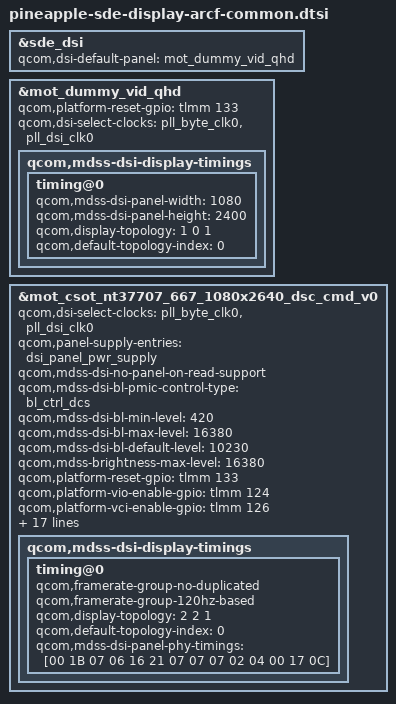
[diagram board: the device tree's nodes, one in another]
/* This is derivated from qcom pineapple-sde-display-mtp.dtsi */

#include "pineapple-sde-display.dtsi"
#include "dsi-panel-mot-dummy-qhd-video.dtsi"
#include "dsi-panel-mot-csot-nt37707-667-1080x2640-dsc-cmd-common_v0.dtsi"

&sde_dsi {
	qcom,dsi-default-panel = <&mot_dummy_vid_qhd>;
};

&mot_dummy_vid_qhd {
       qcom,mdss-dsi-display-timings {
                timing@0{
                       qcom,mdss-dsi-panel-width = <1080>;
                       qcom,mdss-dsi-panel-height = <2400>;
               };
       };
};

//&L11B {
//       regulator-min-microvolt = <1230000>;
//       regulator-max-microvolt = <1280000>;
//       qcom,init-voltage = <1250000>;
//};

//&sde_dsi1 {
//	vddio-supply = <&L10B>;
//	vdd-supply = <&L11B>;
//	vci-supply = <&L9B>;
//};

&mot_csot_nt37707_667_1080x2640_dsc_cmd_v0 {
	qcom,dsi-select-clocks = "pll_byte_clk0", "pll_dsi_clk0";
	qcom,panel-supply-entries = <&dsi_panel_pwr_supply>;
	qcom,mdss-dsi-no-panel-on-read-support;
	qcom,mdss-dsi-bl-pmic-control-type = "bl_ctrl_dcs";
	qcom,mdss-dsi-bl-min-level = <420>;
	qcom,mdss-dsi-bl-max-level = <16380>;
	qcom,mdss-dsi-bl-default-level = <10230>;
	qcom,mdss-brightness-max-level = <16380>;
	qcom,platform-reset-gpio = <&tlmm 133 0>;
	qcom,platform-vio-enable-gpio = <&tlmm 124 0>;
	qcom,platform-vci-enable-gpio = <&tlmm 126 0>;
	qcom,platform-vdd-enable-gpio = <&tlmm 125 0>;
	qcom,bl-dsc-cmd-state = "dsi_hs_mode";
	qcom,mdss-dsi-bl-inverted-dbv;
	qcom,mdss-dsi-bl-is-exponent;


	qcom,mdss-dsi-panel-status-check-mode = "reg_read";
	qcom,mdss-dsi-panel-status-command = [06 01 00 01 00 00 01 0a];
	qcom,mdss-dsi-panel-status-command-state = "dsi_lp_mode";
	qcom,mdss-dsi-panel-status-value = <0x9c>;
	qcom,mdss-dsi-panel-status-read-length = <1>;
	//qcom,esd-check-enabled;
	qcom,cellid-read-enabled;
	qcom,mdss-dsi-panel-cellid-read-length = <36>;
	qcom,mdss-dsi-panel-cellid-offset = <13>;
	qcom,mdss-dsi-panel-cellid-command = [
		06 01 00 01 00 00 01 AC];
	qcom,mdss-dsi-display-timings {
		timing@0 { //120
			qcom,framerate-group-no-duplicated;
			qcom,framerate-group-120hz-based;
			//qcom,mdss-dsi-panel-clockrate = <777000000>;
			qcom,display-topology = <2 2 1>;
			qcom,default-topology-index = <0>;
			qcom,mdss-dsi-panel-phy-timings = [00 1B 07 06 16 21 07
							07 07 02 04 00 17 0C];
		};
	};
};

&mot_dummy_vid_qhd {
	qcom,platform-reset-gpio = <&tlmm 133 0>;

	qcom,dsi-select-clocks = "pll_byte_clk0", "pll_dsi_clk0";
	qcom,mdss-dsi-display-timings {
		timing@0 {
			qcom,display-topology = <1 0 1>;
			qcom,default-topology-index = <0>;
		};
	};
};
